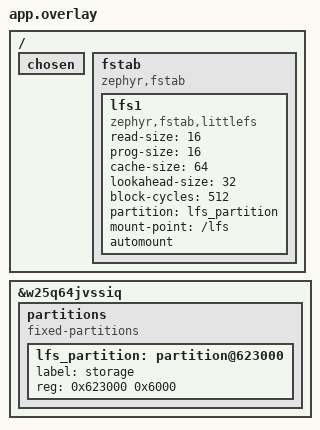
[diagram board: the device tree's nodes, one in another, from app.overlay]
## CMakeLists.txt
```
cmake_minimum_required(VERSION 3.2.0)

set(BOARD   frdm_mcxn947/mcxn947/cpu0)
#set(EXTRA_CONF_FILE mcumgr.conf)

find_package(Zephyr REQUIRED HINTS $ENV{ZEPHYR_BASE})

project(nrf7002dk-files-system)


target_sources(app PRIVATE src/main.c)
```

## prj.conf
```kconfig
# fs_dirent structures are big.
CONFIG_MAIN_STACK_SIZE=4096

# Let __ASSERT do its job
CONFIG_DEBUG=y
CONFIG_GPIO=y
CONFIG_LOG=y
CONFIG_LOG_MODE_MINIMAL=y

CONFIG_FLASH=y
CONFIG_FLASH_MAP=y
CONFIG_FILE_SYSTEM=y
CONFIG_FILE_SYSTEM_LITTLEFS=y
#CONFIG_LITTLEFS_LOG=y

# Using SPI FLASH 
CONFIG_SPI=y
CONFIG_SPI_NOR=y
CONFIG_SPI_NOR_FLASH_LAYOUT_PAGE_SIZE=4096

# Enable the SHELL and the File System commands
CONFIG_CONSOLE=y
CONFIG_SHELL=y
CONFIG_FLASH_SHELL=y
#CONFIG_FLASH_LOG=y
CONFIG_FILE_SYSTEM_SHELL=y
CONFIG_FILE_SYSTEM_SHELL_MOUNT_COMMAND=y
# Heap pool is require by the shell command 
CONFIG_HEAP_MEM_POOL_SIZE=8192

# Enable the tests
```

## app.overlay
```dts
/ {
    chosen{
        /*zephyr,console = &usb_serial;*/
		/*zephyr,shell-uart = &usb_serial;*/
        /*zephyr,flash-controller = &flash;*/
        
    };

    fstab {
		compatible = "zephyr,fstab";
		status="okay";
		lfs1: lfs1 {
			compatible = "zephyr,fstab,littlefs";
			status="okay";
			read-size = <16>;
			prog-size = <16>;
			cache-size = <64>;
			lookahead-size = <32>;
			block-cycles = <512>;
			partition = <&lfs_partition>;
			mount-point = "/lfs";
            automount;
            //disk-access;
		};
	};

};


&w25q64jvssiq{
	partitions {
					compatible = "fixed-partitions"; 
					#address-cells = < 0x1 >;        
					#size-cells = < 0x1 >;           
					lfs_partition: partition@623000 {
						label = "storage";     
						reg = < 0x623000 0x6000 >; 
						phandle = < 0x27 >;     
					};
				};
};
```

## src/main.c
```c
#include<zephyr/kernel.h>
#include<zephyr/logging/log.h>
#include<zephyr/drivers/gpio.h>

static struct gpio_dt_spec led = GPIO_DT_SPEC_GET(DT_NODELABEL(red_led), gpios);
LOG_MODULE_REGISTER(main, LOG_LEVEL_DBG);

int main()

{
    gpio_pin_configure_dt(&led, GPIO_OUTPUT);
    while(1)
    {

        k_msleep(1000);
        gpio_pin_toggle_dt(&led);
        //LOG_INF("Hello world");
    }
}
```
